# max32630 register map
Vendor: Maxim Integrated; Series: max3263x; File version: 1.2
CPU: CM4 r0p1, little endian, no MPU, FPU, 3 interrupt priority bits
Registers are 32-bit, read-write, reset 0x0 unless marked. A register's access mark holds for its fields unless they carry their own. Offsets are from the block's base; [hi:lo] are bit positions; {n}, {i} and the like mark numbered series.

## OWM — 1-Wire Master Interface
Base 0x4001E000
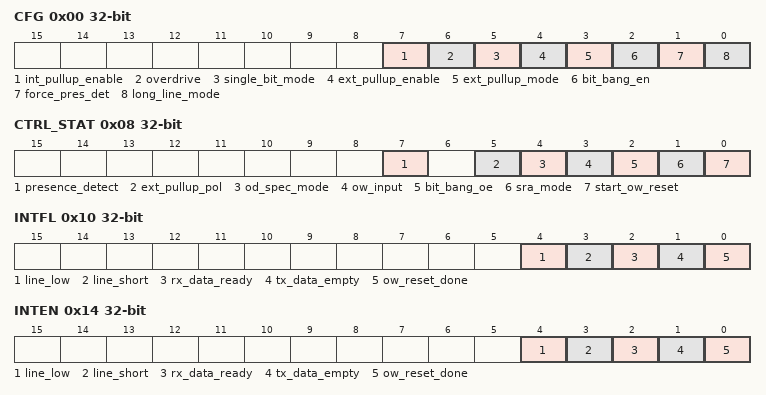
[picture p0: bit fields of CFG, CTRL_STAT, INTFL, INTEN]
0x00 CFG — 1-Wire Master Configuration
  [7] int_pullup_enable — Enable internal pullup.
  [6] overdrive — Enables overdrive speed for 1-Wire operations.
  [5] single_bit_mode — Enable Single Bit TX/RX Mode
  [4] ext_pullup_enable — Enable External FET Pullup
  [3] ext_pullup_mode — Provide an extra output to control an external pullup.
  [2] bit_bang_en — Bit Bang Enable
  [1] force_pres_det — Force Line During Presence Detect
  [0] long_line_mode
0x04 CLK_DIV_1US — 1-Wire Master Clock Divisor
  [7:0] divisor — Clock Divisor for 1MHz
0x08 CTRL_STAT — 1-Wire Master Control/Status
  [7] presence_detect ro — Presence Pulse Detected
  [5] ext_pullup_pol — External FET Pullup Polarity
  [4] od_spec_mode — Enable Overdrive Spec Timing Mode
  [3] ow_input ro — OW Input State
  [2] bit_bang_oe — Bit Bang Output Enable
  [1] sra_mode
  [0] start_ow_reset
0x0C DATA — 1-Wire Master Data Buffer
  [7:0] tx_rx — Tx/Rx Buffer
0x10 INTFL — 1-Wire Master Interrupt Flags
  [4] line_low write-1-clears — OW Line Low Detected Interrupt Flag
  [3] line_short write-1-clears — OW Line Short Detected Interrupt Flag
  [2] rx_data_ready write-1-clears — Rx Data Ready Interrupt Flag
  [1] tx_data_empty write-1-clears — Tx Data Empty Interrupt Flag
  [0] ow_reset_done write-1-clears — OW Reset Sequence Completed
0x14 INTEN — 1-Wire Master Interrupt Enables
  [4] line_low — OW Line Low Detected Interrupt Enable
  [3] line_short — OW Line Short Detected Interrupt Enable
  [2] rx_data_ready — Rx Data Ready Interrupt Enable
  [1] tx_data_empty — Tx Data Empty Interrupt Enable
  [0] ow_reset_done — OW Reset Sequence Completed

## ADC — ADC / AFE
Base 0x4001F000
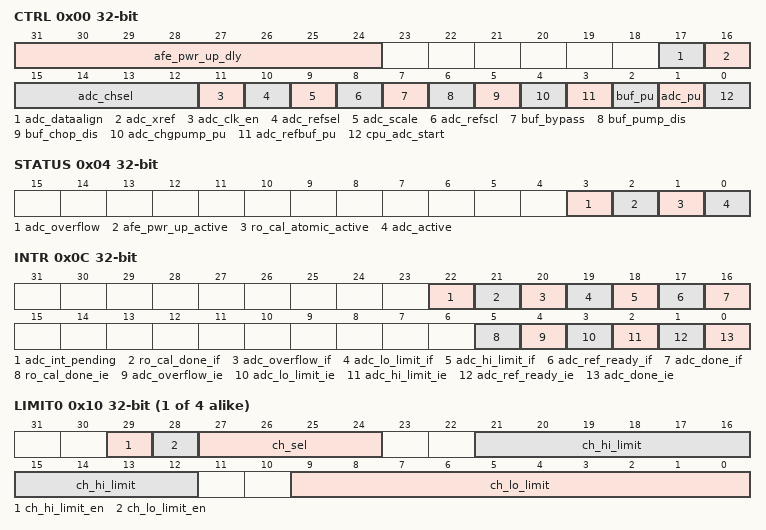
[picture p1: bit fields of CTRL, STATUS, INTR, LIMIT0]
0x00 CTRL — ADC Control
  [31:24] afe_pwr_up_dly — Delay from ADC Powerup Until ADC Ready Asserted
  [17] adc_dataalign — ADC Data Alignment Select
  [16] adc_xref — Enable Use of ADC External Reference
  [15:12] adc_chsel — ADC Channel Select
  [11] adc_clk_en — ADC Clock Enable
  [10] adc_refsel — ADC Reference Select [INTERNAL USE ONLY]
  [9] adc_scale
  [8] adc_refscl — ADC Reference Scale
  [7] buf_bypass — Bypass Input Buffer
  [6] buf_pump_dis — Disable Charge Pump Out to Input Buffer [INTERNAL USE ONLY]
  [5] buf_chop_dis — ADC Input Buffer Chop Disable [INTERNAL USE ONLY]
  [4] adc_chgpump_pu — ADC Charge Pump Power Up
  [3] adc_refbuf_pu — ADC Reference Buffer Power Up
  [2] buf_pu — ADC Input Buffer Power Up
  [1] adc_pu — ADC Power Up
  [0] cpu_adc_start — Start ADC Conversion
0x04 STATUS — ADC Status
  [3] adc_overflow ro
  [2] afe_pwr_up_active ro — AFE Power Up Delay Active
  [1] ro_cal_atomic_active ro — RO Frequency Calibration Active (If Atomic)
  [0] adc_active ro — ADC Conversion In Progress
0x08 DATA — ADC Output Data
  [15:0] adc_data ro — ADC Converted Sample Data Output
0x0C INTR — ADC Interrupt Control Register
  [22] adc_int_pending ro — ADC Interrupt Pending Status
  [21] ro_cal_done_if write-1-clears — RO Cal Done Interrupt Flag
  [20] adc_overflow_if write-1-clears — ADC Overflow Interrupt Flag
  [19] adc_lo_limit_if write-1-clears — ADC Lo Limit Monitor Interrupt Flag
  [18] adc_hi_limit_if write-1-clears — ADC Hi Limit Monitor Interrupt Flag
  [17] adc_ref_ready_if write-1-clears — ADC Reference Ready Interrupt Flag
  [16] adc_done_if write-1-clears — ADC Done Interrupt Flag
  [5] ro_cal_done_ie — RO Cal Done Interrupt Enable
  [4] adc_overflow_ie — ADC Overflow Interrupt Enable
  [3] adc_lo_limit_ie — ADC Lo Limit Monitor Interrupt Enable
  [2] adc_hi_limit_ie — ADC Hi Limit Monitor Interrupt Enable
  [1] adc_ref_ready_ie — ADC Reference Ready Interrupt Enable
  [0] adc_done_ie — ADC Done Interrupt Enable
{0x10+4i} LIMIT{i} (i=0..3) — ADC Limit {i}
  [29] ch_hi_limit_en — High Limit Monitoring Enable
  [28] ch_lo_limit_en — Low Limit Monitoring Enable
  [27:24] ch_sel — ADC Channel Select
  [21:12] ch_hi_limit — High Limit Threshold
  [9:0] ch_lo_limit — Low Limit Threshold
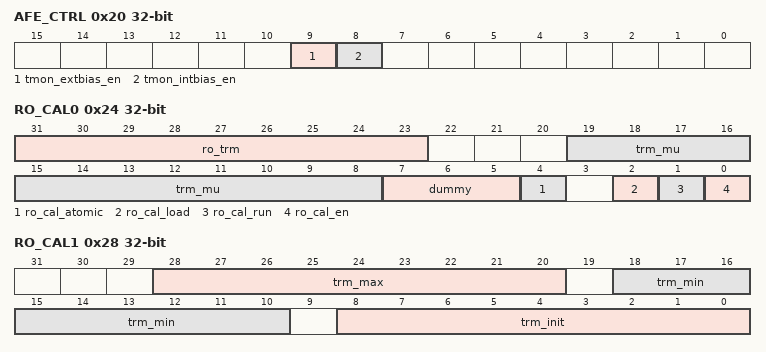
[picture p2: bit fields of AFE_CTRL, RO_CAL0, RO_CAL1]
0x20 AFE_CTRL — AFE Control Register
  [9] tmon_extbias_en — Enable external temperature measurement bias generator
  [8] tmon_intbias_en — Enable internal temperature measurement bias generator
0x24 RO_CAL0 — RO Trim Calibration Register 0
  [31:23] ro_trm — RO Trim Calibration Result
  [19:8] trm_mu — RO Trim Adaptation Gain
  [7:5] dummy — Dummy Write Field
  [4] ro_cal_atomic — RO Calibration Run Atomic
  [2] ro_cal_load — RO Calibration Load Initial Value
  [1] ro_cal_run — RO Calibration Run
  [0] ro_cal_en — RO Calibration Enable
0x28 RO_CAL1 — RO Trim Calibration Register 1
  [28:20] trm_max — RO Trim Minimum Adaptive Limit
  [18:10] trm_min — RO Trim Maximum Adaptive Limit
  [8:0] trm_init — RO Trim Initial Value
0x2C RO_CAL2 — RO Trim Calibration Register 2
  [7:0] auto_cal_done_cnt — Auto Cal Time Delay for Atomic Calibration (in milliseconds)

## SPIS — SPI Slave Interface
Base 0x40020000
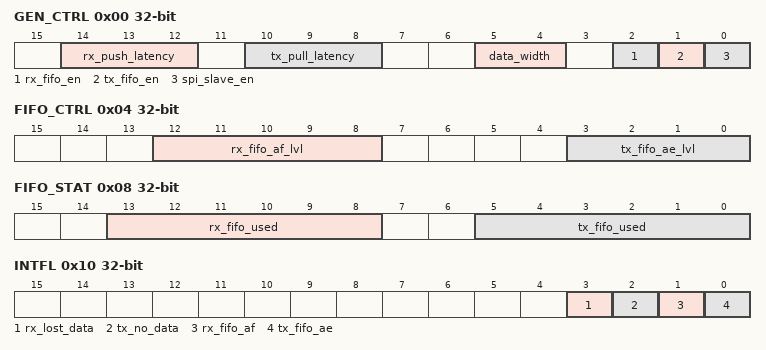
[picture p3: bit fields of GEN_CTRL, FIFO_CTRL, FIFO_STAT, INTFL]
0x00 GEN_CTRL — SPI Slave General Control Register
  [14:12] rx_push_latency
  [10:8] tx_pull_latency
  [5:4] data_width
  [2] rx_fifo_en — RX FIFO Enable
  [1] tx_fifo_en — TX FIFO Enable
  [0] spi_slave_en — Enable/Disable SPI Slave
0x04 FIFO_CTRL — SPI Slave FIFO Control Register
  [12:8] rx_fifo_af_lvl — RX FIFO Almost Full Threshold Level
  [3:0] tx_fifo_ae_lvl — TX FIFO Almost Empty Threshold Level
0x08 FIFO_STAT — SPI Slave FIFO Status Register
  [13:8] rx_fifo_used ro — RX FIFO Bytes Used
  [5:0] tx_fifo_used ro — TX FIFO Bytes Used
0x10 INTFL — SPI Slave Interrupt Flags
  [3] rx_lost_data write-1-clears — Data Lost Due to RX FIFO Overflow Interrupt Flag
  [2] tx_no_data write-1-clears — No Data in TX FIFO Interrupt Flag
  [1] rx_fifo_af write-1-clears — RX FIFO Almost Full Interrupt Flag
  [0] tx_fifo_ae write-1-clears — TX FIFO Almost Empty Interrupt Flag
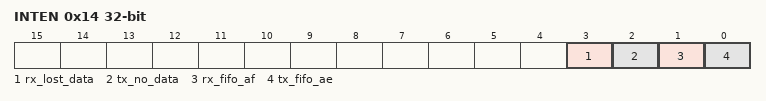
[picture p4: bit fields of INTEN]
0x14 INTEN — SPI Slave Interrupt Enable/Disable Settings
  [3] rx_lost_data — Data Lost Due to RX FIFO Overflow Interrupt Enable
  [2] tx_no_data — No Data in TX FIFO Interrupt Enable
  [1] rx_fifo_af — RX FIFO Almost Full Interrupt Enable
  [0] tx_fifo_ae — TX FIFO Almost Empty Interrupt Enable
